# D1H.pdf register map
Vendor: Allwinner; Series: D1H.pdf; File version: 0.1
CPU: XuanTie C906 RISC-V CPU 0, little endian, MPU, FPU, double-precision FPU, 0 interrupt priority bits
Registers are 32-bit, read-write, reset 0x0 unless marked. A register's access mark holds for its fields unless they carry their own. Offsets are from the block's base; [hi:lo] are bit positions; {n}, {i} and the like mark numbered series; 'fields as' and 'values as' point back to an identical list.

## DMIC
Base 0x02031000
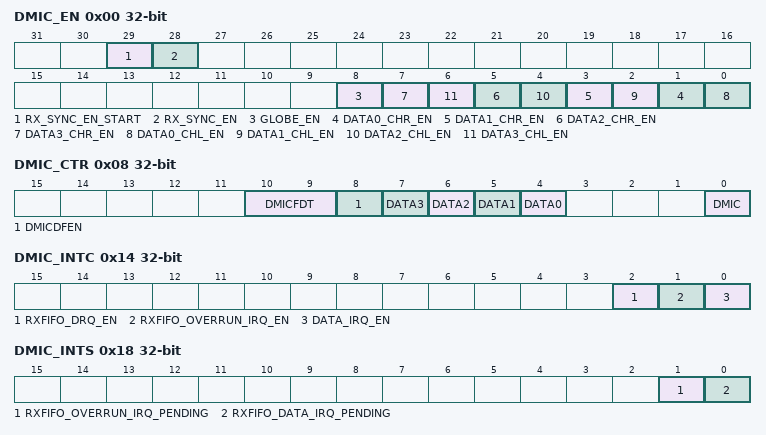
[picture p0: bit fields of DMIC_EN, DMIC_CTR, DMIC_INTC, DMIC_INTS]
0x00 DMIC_EN — DMIC Enable Control Register
  [all] fields
    0=Disabled; 1=Enabled
  [29] RX_SYNC_EN_START — Audio Subsys RX Synchronize Enable Start Includes Audio codec/I2S0/I2S1/I2S2/DMIC. The bit takes effect only when RX_SYNC_EN is set to 1. 0: Disabled 1: Enabled
  [28] RX_SYNC_EN — DMIC RX Synchronize Enable 0: Disabled 1: Enabled
  [8] GLOBE_EN — DMIC Globe Enable 0: Disabled 1: Enabled
  [2n+1] DATA{n}_CHR_EN (n=0..3) — DATA{n} Right Channel Enable 0: Disabled 1: Enabled
  [2n] DATA{n}_CHL_EN (n=0..3) — DATA{n} Left Channel Enable 0: Disabled 1: Enabled
0x04 DMIC_SR — DMIC Sample Rate Register
  [2:0] DMIC_SR — Sample Rate of DMIC 000: 48 kHz 010: 24 kHz 100: 12 kHz 110: Reserved 001: 32 kHz 011: 16 kHz 101: 8 kHz 111: Reserved 44.1 kHz/22.05 kHz/11.025 kHz can be supported by Audio PLL Configure Bit.
    0=_48_kHz; 2=_24_kHz; 4=_12_kHz; 1=_32_kHz; 3=_16_kHz; 5=_8_kHz
0x08 DMIC_CTR — DMIC Control Register
  [10:9] DMICFDT — DMIC RXFIFO Delay Time for Writing Data after GLOBE_EN 00: 5 ms 01: 10 ms 10: 20 ms 11: 30 ms
    0=_5_ms; 1=_10_ms; 2=_20_ms; 3=_30_ms
  [8] DMICDFEN — DMIC RXFIFO Delay Function for Writing Data after GLOBE_EN 0: Disabled 1: Enabled
    0=Disabled; 1=Enabled
  [n+4] DATA{n} (n=0..3) — Left Data and Right Data Swap Enable 0: Disabled 1: Enabled
    0=Disabled; 1=Enabled
  [0] DMIC — Oversample Rate 0: 128 (Supports 8 kHz to 24 kHz) 1: 64 (Supports 16 kHz to 48 kHz)
    0=128 (Supports 8 kHz to 24 kHz); 1=64 (Supports 16 kHz to 48 kHz)
0x10 DMIC_DATA
  [31:0] DMIC_DATA ro
0x14 DMIC_INTC — DMIC Interrupt Control Register
  [all] fields
    0=Disabled; 1=Enabled
  [2] RXFIFO_DRQ_EN — DMIC RXFIFO Data Available DRQ Enable 0: Disabled 1: Enabled
  [1] RXFIFO_OVERRUN_IRQ_EN — DMIC RXFIFO Overrun IRQ Enable 0: Disabled 1: Enabled
  [0] DATA_IRQ_EN — DMIC RXFIFO Data Available IRQ Enable 0: Disabled 1: Enabled
0x18 DMIC_INTS — DMIC Interrupt Status Register
  [1] RXFIFO_OVERRUN_IRQ_PENDING write-1-clears — DMIC RXFIFO Overrun Pending Interrupt 0: No pending IRQ 1: RXFIFO overrun pending IRQ Writing ‘1’ to clear this interrupt or automatically clear if the interrupt condition fails.
    0=No pending IRQ; 1=RXFIFO (RXFIFO overrun pending IRQ Writing ‘1’ to clear this interrupt or automatically clear if the interrupt condition fails.)
  [0] RXFIFO_DATA_IRQ_PENDING write-1-clears — DMIC RXFIFO Data Available Pending Interrupt 0: No pending IRQ 1: Data available pending IRQ Writing ‘1’ to clear this interrupt or automatically clear if the interrupt condition fails.
    0=No pending IRQ; 1=Data available pending IRQ Writing ‘1’ to clear this interrupt or automatically clear if the interrupt condition fails
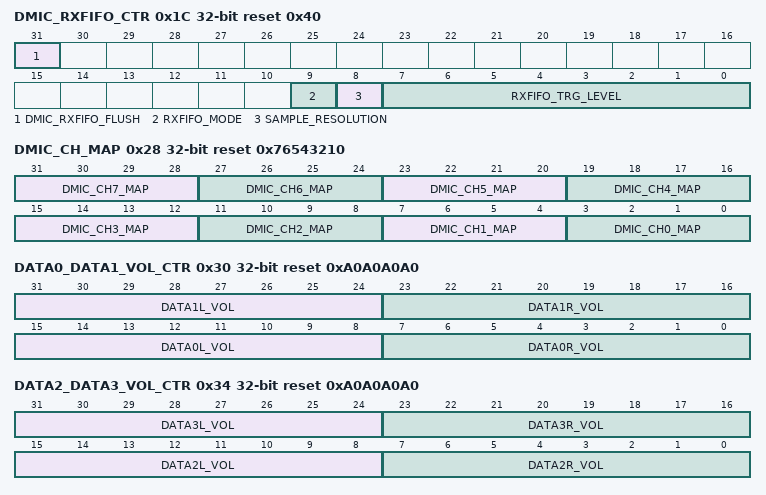
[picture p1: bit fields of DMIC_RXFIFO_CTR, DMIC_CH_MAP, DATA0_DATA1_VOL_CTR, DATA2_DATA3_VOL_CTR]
0x1C DMIC_RXFIFO_CTR reset 0x40 — DMIC RXFIFO Control Register
  [31] DMIC_RXFIFO_FLUSH write-1-clears — DMIC RXFIFO Flush Writing ‘1’ to flush RXFIFO, self clear to ‘0’
  [9] RXFIFO_MODE — RXFIFO Output Mode (Mode 0, 1) 0: Expanding ‘0’ at LSB of RXFIFO register 1: Expanding received sample sign bit at MSB of RXFIFO register For 24-bit received audio sample: Mode 0: RXDATA[31:0] = {RXFIFO_O[20:0], 11’h0} Mode 1: RXDATA[31:0] = {8{RXFIFO_O[20]}, RXFIFO_O[20:0], 3’h0} For 16-bit received audio sample: Mode 0: RXDATA[31:0] = {RXFIFO_O[20:5], 16’h0} Mode 1: RXDATA[31:0] = {16{RXFIFO_O[20]}, RXFIFO_O[20:5]}
    0=Expanding__quote_0_quote_ (Expanding ‘0’ at LSB of RXFIFO register); 1=Expanding received sample sign bit at MSB of RXFIFO register For 24-bit received audio sample: Mode 0: RXDATA[31:0] = {RXFIFO_O[20:0], 11’h0} Mode 1: RXDATA[31:0] = {8{RXFIFO_O[20]}, RXFIFO_O[20:0], 3’h0} For 16-bit received audio sample: Mode 0: RXDATA[31:0] = {RXFIFO_O[20:5], 16’h0} Mode 1: RXDATA[31:0] = {16{RXFIFO_O[20]}, RXFIFO_O[20:5]}
  [8] SAMPLE_RESOLUTION — 0: 16-bit 1: 24- bit
    0=_16_bit; 1=_24_minus__bit (24- bit)
  [7:0] RXFIFO_TRG_LEVEL — RXFIFO Trigger Level (TRLV[7:0]) Interrupt and DMA request trigger level for DMIC RXFIFO normal condition IRQ/DRQ Generated when WLEVEL > TRLV[7:0]) WLEVEL represents the number of valid samples in the DMIC RXFIFO
0x20 DMIC_RXFIFO_STA reset 0x100 — DMIC RXFIFO Status Register
  [7:0] DMIC_DATA_CNT — DMIC RXFIFO Available Sample Word Counter
0x24 DMIC_CH_NUM reset 0x1 — DMIC Channel Numbers Register
  [2:0] DMIC_CH_NUM — DMIC enable channel numbers are (N + 1).
0x28 DMIC_CH_MAP reset 0x76543210 — DMIC Channel Mapping Register
  [all] fields
    0=DATA0 Left Channel; 1=DATA0 Right Channel; 2=DATA1 Left Channel; 3=DATA1 Right Channel; 4=DATA2 Left Channel; 5=DATA2 Right Channel; 6=DATA3 Left Channel; 7=DATA3 Right Channel
  [4n+3:4n] DMIC_CH{n}_MAP (n=1..7) — DMIC Channel {n} Mapping 0000: DATA0 Left Channel 0001: DATA0 Right Channel 0010: DATA1 Left Channel 0011: DATA1 Right Channel 0100: DATA2 Left Channel 0101: DATA2 Right Channel 0110: DATA3 Left Channel 0111: DATA3 Right Channel
  [3:0] DMIC_CH0_MAP — DMIC Channel0 Mapping 0000: DATA0 Left Channel 0001: DATA0 Right Channel 0010: DATA1 Left Channel 0011: DATA1 Right Channel 0100: DATA2 Left Channel 0101: DATA2 Right Channel 0110: DATA3 Left Channel 0111: DATA3 Right Channel
0x2C DMIC_CNT — DMIC Counter Register
  [31:0] DMIC_CNT — RX Sample Counter The audio sample number of writing into RXFIFO. When one sample is read by Digital Audio Engine, the RX sample counter register increases by one. The RX sample counter register can be set to any initial valve at any time. After being updated by the initial value, the counter register should count on the base of this initial value.
0x30 DATA0_DATA1_VOL_CTR reset 0xA0A0A0A0 — Data0 and Data1 Volume Control Register
  [all] fields
    0=Mute; 1=_minus_119_point_25_dB (-119.25 dB ...); 159=_minus_0_point_75_dB (-0.75 dB); 160=_0_dB; 161=_0_point_75_dB (0.75 dB ...); 255=_71_point_25_dB (71.25 dB)
  [31:24] DATA1L_VOL — Data1 Left Channel Volume Control (-119.25 dB to 71.25 dB, 0.75 dB/Step) 0x00: Mute 0x01: -119.25 dB ... 0x9F: -0.75 dB 0xA0: 0 dB 0xA1: 0.75 dB ... 0xFF: 71.25 dB
  [23:16] DATA1R_VOL — Data1 Right Channel Volume Control (-119.25 dB to 71.25 dB, 0.75 dB/Step) 0x00: Mute 0x01: -119.25 dB ... 0x9F: -0.75 dB 0xA0: 0 dB 0xA1: 0.75 dB ... 0xFF: 71.25 dB
  [15:8] DATA0L_VOL — Data0 Left Channel Volume Control (-119.25 dB to 71.25 dB, 0.75 dB/Step) 0x00: Mute 0x01: -119.25 dB ... 0x9F: -0.75 dB 0xA0: 0 dB 0xA1: 0.75 dB ... 0xFF: 71.25 dB
  [7:0] DATA0R_VOL — Data0 Right Channel Volume Control (-119.25 dB to 71.25 dB, 0.75 dB/Step) 0x00: Mute 0x01: -119.25 dB ... 0x9F: -0.75 dB 0xA0: 0 dB 0xA1: 0.75 dB ... 0xFF: 71.25 dB
0x34 DATA2_DATA3_VOL_CTR reset 0xA0A0A0A0 — Data2 And Data3 Volume Control Register
  [all] fields
    values as the fields of DATA0_DATA1_VOL_CTR
  [31:24] DATA3L_VOL — Data3 Light Channel Volume Control (-119.25 dB to 71.25 dB, 0.75 dB/Step) 0x00: Mute 0x01: -119.25 dB ... 0x9F: -0.75 dB 0xA0: 0 dB 0xA1: 0.75 dB ... 0xFF: 71.25 dB
  [23:16] DATA3R_VOL — Data3 Right Channel Volume Control (-119.25 dB to 71.25 dB, 0.75 dB/Step) 0x00: Mute 0x01: -119.25 dB ... 0x9F: -0.75 dB 0xA0: 0 dB 0xA1: 0.75 dB ... 0xFF: 71.25 dB
  [15:8] DATA2L_VOL — Data2 Light Channel Volume Control (-119.25 dB to 71.25 dB, 0.75 dB/Step) 0x00: Mute 0x01: -119.25 dB ... 0x9F: -0.75 dB 0xA0: 0 dB 0xA1: 0.75 dB ... 0xFF: 71.25 dB
  [7:0] DATA2R_VOL — Data2 Right Channel Volume Control (-119.25 dB to 71.25 dB, 0.75 dB/Step) 0x00: Mute 0x01: -119.25 dB ... 0x9F: -0.75 dB 0xA0: 0 dB 0xA1: 0.75 dB ... 0xFF: 71.25 dB
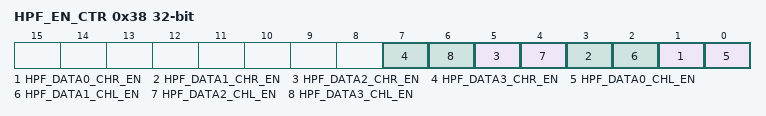
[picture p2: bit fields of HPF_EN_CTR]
0x38 HPF_EN_CTR — High Pass Filter Enable Control Register
  [all] fields
    0=Disabled; 1=Enabled
  [2n+1] HPF_DATA{n}_CHR_EN (n=0..3) — High Pass Filter DATA{n} Right Channel Enable 0: Disabled 1: Enabled
  [2n] HPF_DATA{n}_CHL_EN (n=0..3) — High Pass Filter DATA{n} Left Channel Enable 0: Disabled 1: Enabled
0x3C HPF_COEF_REG reset 0xFFAA45 — High Pass Filter Coefficient Register
  [31:0] HPF_COE — High Pass Filter Coefficient
0x40 HPF_GAIN_REG reset 0xFFD522 — High Pass Filter Gain Register
  [31:0] HPF_GAIN — High Pass Filter Gain
